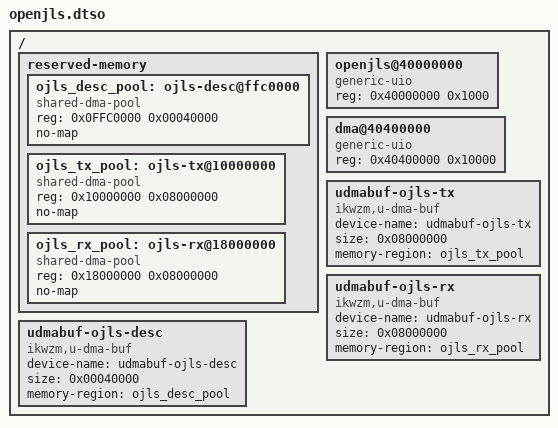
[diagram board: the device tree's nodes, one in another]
// Copyright (C) 2026 Vitor Mendes Camilo
// SPDX-License-Identifier: GPL-3.0-only
//
// This file is part of OpenJLS-Demos. Available under GPLv3 or a
// commercial license. See LICENSE.md and README.md for details.
//
// openjls.dtso: PYNQ-Z2 overlay: UIO for the core and DMA, carveout-backed u-dma-bufs
//
// U-Boot applies it at boot (setup_bootargs.sh); a runtime configfs overlay
// reserves nothing. no-map pools round each allocation up to a power of two,
// so keep every buffer equal to its pool and a power of two. PYNQ's own
// fabric@40000000 UIO node overlaps ours harmlessly: UIO does not request the
// region, and the server picks its devices by name.
//
// Compile: dtc -@ -O dtb -o openjls.dtbo openjls.dtso

/dts-v1/;
/plugin/;

/ {
    fragment@0 {
        target-path = "/";
        __overlay__ {
            #address-cells = <1>;
            #size-cells = <1>;

            reserved-memory {
                #address-cells = <1>;
                #size-cells = <1>;
                ranges;

                /* ARM rejects a non-reusable shared-dma-pool without no-map. */
                ojls_desc_pool: ojls-desc@ffc0000 {
                    compatible = "shared-dma-pool";
                    reg = <0x0FFC0000 0x00040000>;
                    no-map;
                };

                ojls_tx_pool: ojls-tx@10000000 {
                    compatible = "shared-dma-pool";
                    reg = <0x10000000 0x08000000>;
                    no-map;
                };

                ojls_rx_pool: ojls-rx@18000000 {
                    compatible = "shared-dma-pool";
                    reg = <0x18000000 0x08000000>;
                    no-map;
                };
            };

            openjls@40000000 {
                compatible = "generic-uio";
                reg = <0x40000000 0x1000>;
            };

            dma@40400000 {
                compatible = "generic-uio";
                reg = <0x40400000 0x10000>;
                /* No IRQs: the server polls. */
            };

            udmabuf-ojls-tx {
                compatible = "ikwzm,u-dma-buf";
                device-name = "udmabuf-ojls-tx";
                size = <0x08000000>;
                memory-region = <&ojls_tx_pool>;
            };

            /* Bounds the input too: the server reserves worst-case
             * output headroom, so the largest image is ~102 MiB. */
            udmabuf-ojls-rx {
                compatible = "ikwzm,u-dma-buf";
                device-name = "udmabuf-ojls-rx";
                size = <0x08000000>;
                memory-region = <&ojls_rx_pool>;
            };

            udmabuf-ojls-desc {
                compatible = "ikwzm,u-dma-buf";
                device-name = "udmabuf-ojls-desc";
                size = <0x00040000>;
                memory-region = <&ojls_desc_pool>;
            };
        };
    };
};
